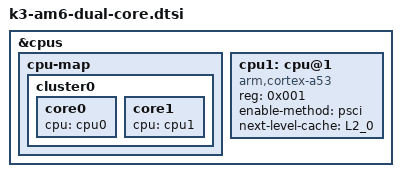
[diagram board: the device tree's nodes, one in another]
// SPDX-License-Identifier: GPL-2.0
/*
 * Device Tree Source for AM6 SoC Family in Dual core configuration
 *
 * Copyright (C) 2016-2017 Texas Instruments Incorporated - http://www.ti.com/
 */

&cpus {
	cpu-map {
		cluster0: cluster0 {
			core0 {
				cpu = <&cpu0>;
			};

			core1 {
				cpu = <&cpu1>;
			};
		};
	};

	/* CPU0 already defined */

	cpu1: cpu@1 {
		compatible = "arm,cortex-a53","arm,armv8";
		reg = <0x001>;
		device_type = "cpu";
		enable-method = "psci";
		next-level-cache = <&L2_0>;
	};
};
